AUTOSAR XML (schema 4-2-2)
package /MICROSAR_SWCS_DEV/ComM_swc/ComponentTypes
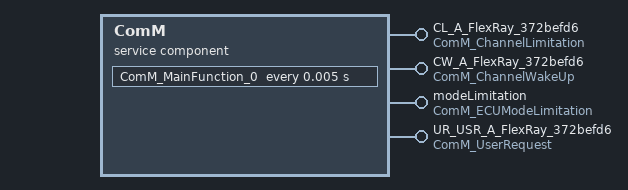
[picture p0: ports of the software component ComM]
  service sw component type ComM
    4 x provide port:
      CL_A_FlexRay_372befd6: provided-com-specs=[{operation=GetInhibitionStatus, queue-length=1}, {operation=LimitChannelToNoComMode, queue-length=1}], provided-interface=ComM_ChannelLimitation
      CW_A_FlexRay_372befd6: provided-com-specs=[{operation=GetInhibitionStatus, queue-length=1}, {operation=PreventWakeUp, queue-length=1}], provided-interface=ComM_ChannelWakeUp
      modeLimitation: provided-interface=ComM_ECUModeLimitation
        provided-com-specs:
          operation=LimitECUToNoComMode, queue-length=1
          operation=ReadInhibitCounter, queue-length=1
          operation=ResetInhibitCounter, queue-length=1
          operation=SetECUGroupClassification, queue-length=1
      UR_USR_A_FlexRay_372befd6: provided-interface=ComM_UserRequest
        provided-com-specs:
          operation=GetCurrentComMode, queue-length=1
          operation=GetMaxComMode, queue-length=1
          operation=GetRequestedComMode, queue-length=1
          operation=RequestComMode, queue-length=1
    behavior ComMInternalBehavior: data-type-mapping=ComMMode_DataTypeMappingSet, included-data-type-set=data-type=[ComM_InhibitionStatusType, ComM_ModeType, ComM_UserHandleType, NetworkHandleType]
      timing event Timer_ComM_MainFunction_0: start-on-event=ComM_MainFunction_0, period=0.005
      12 x operation invoked event:
        OpEventGetCurrentComMode_GetCurrentComMode_UR_USR_A_FlexRay_372befd6: start-on-event=GetCurrentComMode, operation=UR_USR_A_FlexRay_372befd6.GetCurrentComMode
        OpEventGetInhibitionStatus_GetInhibitionStatus_CL_A_FlexRay_372befd6: start-on-event=GetInhibitionStatus, operation=CL_A_FlexRay_372befd6.GetInhibitionStatus
        OpEventGetInhibitionStatus_GetInhibitionStatus_CW_A_FlexRay_372befd6: start-on-event=GetInhibitionStatus, operation=CW_A_FlexRay_372befd6.GetInhibitionStatus
        OpEventGetMaxComMode_GetMaxComMode_UR_USR_A_FlexRay_372befd6: start-on-event=GetMaxComMode, operation=UR_USR_A_FlexRay_372befd6.GetMaxComMode
        OpEventGetRequestedComMode_GetRequestedComMode_UR_USR_A_FlexRay_372befd6: start-on-event=GetRequestedComMode, operation=UR_USR_A_FlexRay_372befd6.GetRequestedComMode
        OpEventLimitChannelToNoComMode_LimitChannelToNoComMode_CL_A_FlexRay_372befd6: start-on-event=LimitChannelToNoComMode, operation=CL_A_FlexRay_372befd6.LimitChannelToNoComMode
        OpEventLimitECUToNoComMode_LimitECUToNoComMode_modeLimitation: start-on-event=LimitECUToNoComMode, operation=modeLimitation.LimitECUToNoComMode
        OpEventPreventWakeUp_PreventWakeUp_CW_A_FlexRay_372befd6: start-on-event=PreventWakeUp, operation=CW_A_FlexRay_372befd6.PreventWakeUp
        OpEventReadInhibitCounter_ReadInhibitCounter_modeLimitation: start-on-event=ReadInhibitCounter, operation=modeLimitation.ReadInhibitCounter
        OpEventRequestComMode_RequestComMode_UR_USR_A_FlexRay_372befd6: start-on-event=RequestComMode, operation=UR_USR_A_FlexRay_372befd6.RequestComMode
        OpEventResetInhibitCounter_ResetInhibitCounter_modeLimitation: start-on-event=ResetInhibitCounter, operation=modeLimitation.ResetInhibitCounter
        OpEventSetECUGroupClassification_SetECUGroupClassification_modeLimitation: start-on-event=SetECUGroupClassification, operation=modeLimitation.SetECUGroupClassification
      port-api-options:
        {enable-take-address=true, error-handling=NO-TRANSFORMER-ERROR-HANDLING, indirect-api=false, port-defined-argument-value{value=CL_A_FlexRay_372befd6_0:0, value-type=NetworkHandleType}, port=CL_A_FlexRay_372befd6}
        {enable-take-address=true, error-handling=NO-TRANSFORMER-ERROR-HANDLING, indirect-api=false, port-defined-argument-value{value=CW_A_FlexRay_372befd6_0:0, value-type=NetworkHandleType}, port=CW_A_FlexRay_372befd6}
        enable-take-address=true, error-handling=NO-TRANSFORMER-ERROR-HANDLING, indirect-api=false, port=modeLimitation
        {enable-take-address=true, error-handling=NO-TRANSFORMER-ERROR-HANDLING, indirect-api=false, port-defined-argument-value{value=UR_USR_A_FlexRay_372befd6_0:0, value-type=ComM_UserHandleType}, port=UR_USR_A_FlexRay_372befd6}
      12 x runnable, all with can-be-invoked-concurrently=true:
        ComM_MainFunction_0
        GetCurrentComMode: symbol=ComM_GetCurrentComMode
        GetInhibitionStatus: symbol=ComM_GetInhibitionStatus
        GetMaxComMode: symbol=ComM_GetMaxComMode
        GetRequestedComMode: symbol=ComM_GetRequestedComMode
        LimitChannelToNoComMode: symbol=ComM_LimitChannelToNoComMode
        LimitECUToNoComMode: symbol=ComM_LimitECUToNoComMode
        PreventWakeUp: symbol=ComM_PreventWakeUp
        ReadInhibitCounter: symbol=ComM_ReadInhibitCounter
        RequestComMode: symbol=ComM_RequestComMode
        ResetInhibitCounter: symbol=ComM_ResetInhibitCounter
        SetECUGroupClassification: symbol=ComM_SetECUGroupClassification
  swc implementation ComMImplementation: behavior=ComMInternalBehavior
    code-descriptors:
      code Default: artifact-descriptors=autosar-engineering-object={short-label=Default, category=SWSRC}
